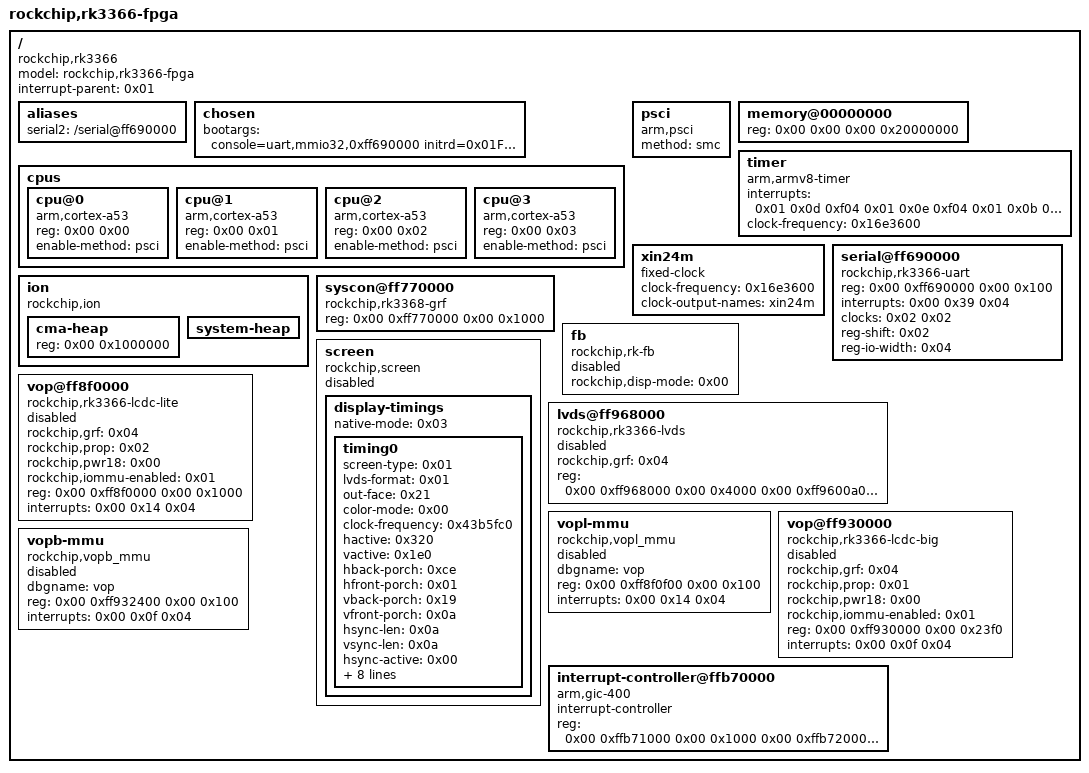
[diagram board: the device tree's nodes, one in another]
/dts-v1/;

/ {
	model = "rockchip,rk3366-fpga";
	compatible = "rockchip,rk3366";
	interrupt-parent = <0x01>;
	#address-cells = <0x02>;
	#size-cells = <0x02>;

	aliases {
		serial2 = "/serial@ff690000";
	};

	chosen {
		bootargs = "console=uart,mmio32,0xff690000 initrd=0x01FFFFF8,0x00800000";
	};

	cpus {
		#address-cells = <0x02>;
		#size-cells = <0x00>;

		cpu@0 {
			device_type = "cpu";
			compatible = "arm,cortex-a53\0arm,armv8";
			reg = <0x00 0x00>;
			enable-method = "psci";
			phandle = <0x05>;
		};

		cpu@1 {
			device_type = "cpu";
			compatible = "arm,cortex-a53\0arm,armv8";
			reg = <0x00 0x01>;
			enable-method = "psci";
			phandle = <0x06>;
		};

		cpu@2 {
			device_type = "cpu";
			compatible = "arm,cortex-a53\0arm,armv8";
			reg = <0x00 0x02>;
			enable-method = "psci";
			phandle = <0x07>;
		};

		cpu@3 {
			device_type = "cpu";
			compatible = "arm,cortex-a53\0arm,armv8";
			reg = <0x00 0x03>;
			enable-method = "psci";
			phandle = <0x08>;
		};
	};

	psci {
		compatible = "arm,psci";
		method = "smc";
	};

	memory@00000000 {
		device_type = "memory";
		reg = <0x00 0x00 0x00 0x20000000>;
	};

	timer {
		compatible = "arm,armv8-timer";
		interrupts = <0x01 0x0d 0xf04 0x01 0x0e 0xf04 0x01 0x0b 0xf04 0x01 0x0a 0xf04>;
		clock-frequency = <0x16e3600>;
	};

	xin24m {
		compatible = "fixed-clock";
		#clock-cells = <0x00>;
		clock-frequency = <0x16e3600>;
		clock-output-names = "xin24m";
		phandle = <0x02>;
	};

	serial@ff690000 {
		compatible = "rockchip,rk3366-uart\0snps,dw-apb-uart";
		reg = <0x00 0xff690000 0x00 0x100>;
		interrupts = <0x00 0x39 0x04>;
		clocks = <0x02 0x02>;
		clock-names = "baudclk\0apb_pclk";
		reg-shift = <0x02>;
		reg-io-width = <0x04>;
		phandle = <0x09>;
	};

	ion {
		compatible = "rockchip,ion";
		#address-cells = <0x01>;
		#size-cells = <0x00>;

		cma-heap {
			reg = <0x00 0x1000000>;
		};

		system-heap {
		};
	};

	syscon@ff770000 {
		compatible = "rockchip,rk3368-grf\0syscon";
		reg = <0x00 0xff770000 0x00 0x1000>;
		phandle = <0x04>;
	};

	fb {
		compatible = "rockchip,rk-fb";
		rockchip,disp-mode = <0x00>;
		status = "disabled";
		phandle = <0x0a>;
	};

	screen {
		compatible = "rockchip,screen";
		status = "disabled";
		phandle = <0x0b>;

		display-timings {
			native-mode = <0x03>;
			phandle = <0x0c>;

			timing0 {
				screen-type = <0x01>;
				lvds-format = <0x01>;
				out-face = <0x21>;
				color-mode = <0x00>;
				clock-frequency = <0x43b5fc0>;
				hactive = <0x320>;
				vactive = <0x1e0>;
				hback-porch = <0xce>;
				hfront-porch = <0x01>;
				vback-porch = <0x19>;
				vfront-porch = <0x0a>;
				hsync-len = <0x0a>;
				vsync-len = <0x0a>;
				hsync-active = <0x00>;
				vsync-active = <0x00>;
				de-active = <0x00>;
				pixelclk-active = <0x00>;
				swap-rb = <0x00>;
				swap-rg = <0x00>;
				swap-gb = <0x00>;
				cabc-lut = <0x00 0x00 0x00 0x00 0x00 0x00 0x00 0x00 0x00 0x00 0x00 0x00 0x00 0x00 0x00 0x00 0x01 0x01 0x01 0x01 0x01 0x01 0x01 0x02 0x02 0x02 0x02 0x02 0x03 0x03 0x03 0x03 0x04 0x04 0x04 0x04 0x05 0x05 0x05 0x05 0x06 0x06 0x06 0x07 0x07 0x07 0x08 0x08 0x09 0x09 0x09 0x0a 0x0a 0x0b 0x0b 0x0b 0x0c 0x0c 0x0d 0x0d 0x0e 0x0e 0x0f 0x0f 0x10 0x10 0x11 0x11 0x12 0x12 0x13 0x13 0x14 0x14 0x15 0x16 0x16 0x17 0x17 0x18 0x19 0x19 0x1a 0x1b 0x1b 0x1c 0x1d 0x1d 0x1e 0x1f 0x1f 0x20 0x21 0x21 0x22 0x23 0x24 0x24 0x25 0x26 0x27 0x28 0x28 0x29 0x2a 0x2b 0x2c 0x2c 0x2d 0x2e 0x2f 0x30 0x31 0x32 0x32 0x33 0x34 0x35 0x36 0x37 0x38 0x39 0x3a 0x3b 0x3c 0x3d 0x3e 0x3f 0x40 0x41 0x42 0x43 0x44 0x45 0x46 0x47 0x48 0x49 0x4a 0x4b 0x4c 0x4d 0x4f 0x50 0x51 0x52 0x53 0x54 0x55 0x57 0x58 0x59 0x5a 0x5b 0x5d 0x5e 0x5f 0x60 0x61 0x63 0x64 0x65 0x66 0x68 0x69 0x6a 0x6c 0x6d 0x6e 0x70 0x71 0x72 0x74 0x75 0x76 0x78 0x79 0x7a 0x7c 0x7d 0x7f 0x80 0x81 0x83 0x84 0x86 0x87 0x89 0x8a 0x8c 0x8d 0x8f 0x90 0x92 0x93 0x95 0x96 0x98 0x99 0x9b 0x9c 0x9e 0xa0 0xa1 0xa3 0xa4 0xa6 0xa8 0xa9 0xab 0xac 0xae 0xb0 0xb1 0xb3 0xb5 0xb6 0xb8 0xba 0xbc 0xbd 0xbf 0xc1 0xc3 0xc4 0xc6 0xc8 0xca 0xcb 0xcd 0xcf 0xd1 0xd3 0xd4 0xd6 0xd8 0xda 0xdc 0xde 0xe0 0xe1 0xe3 0xe5 0xe7 0xe9 0xeb 0xed 0xef 0xf1 0xf3 0xf5 0xf7 0xf9 0xfb 0xfd 0xff>;
				phandle = <0x03>;
			};
		};
	};

	lvds@ff968000 {
		compatible = "rockchip,rk3366-lvds";
		rockchip,grf = <0x04>;
		reg = <0x00 0xff968000 0x00 0x4000 0x00 0xff9600a0 0x00 0x20>;
		reg-names = "mipi_lvds_phy\0mipi_lvds_ctl";
		status = "disabled";
		phandle = <0x0d>;
	};

	vop@ff8f0000 {
		compatible = "rockchip,rk3366-lcdc-lite";
		rockchip,grf = <0x04>;
		rockchip,prop = <0x02>;
		rockchip,pwr18 = <0x00>;
		rockchip,iommu-enabled = <0x01>;
		reg = <0x00 0xff8f0000 0x00 0x1000>;
		interrupts = <0x00 0x14 0x04>;
		status = "disabled";
		phandle = <0x0e>;
	};

	vopl-mmu {
		dbgname = "vop";
		compatible = "rockchip,vopl_mmu";
		reg = <0x00 0xff8f0f00 0x00 0x100>;
		interrupts = <0x00 0x14 0x04>;
		interrupt-names = "vopl_mmu";
		status = "disabled";
		phandle = <0x0f>;
	};

	vop@ff930000 {
		compatible = "rockchip,rk3366-lcdc-big";
		rockchip,grf = <0x04>;
		rockchip,prop = <0x01>;
		rockchip,pwr18 = <0x00>;
		rockchip,iommu-enabled = <0x01>;
		reg = <0x00 0xff930000 0x00 0x23f0>;
		interrupts = <0x00 0x0f 0x04>;
		status = "disabled";
		phandle = <0x10>;
	};

	vopb-mmu {
		dbgname = "vop";
		compatible = "rockchip,vopb_mmu";
		reg = <0x00 0xff932400 0x00 0x100>;
		interrupts = <0x00 0x0f 0x04>;
		interrupt-names = "vop_mmu";
		status = "disabled";
		phandle = <0x11>;
	};

	interrupt-controller@ffb70000 {
		compatible = "arm,gic-400";
		#interrupt-cells = <0x03>;
		#address-cells = <0x00>;
		interrupt-controller;
		reg = <0x00 0xffb71000 0x00 0x1000 0x00 0xffb72000 0x00 0x1000>;
		phandle = <0x01>;
	};

	__symbols__ {
		cpu0 = "/cpus/cpu@0";
		cpu1 = "/cpus/cpu@1";
		cpu2 = "/cpus/cpu@2";
		cpu3 = "/cpus/cpu@3";
		xin24m = "/xin24m";
		uart2 = "/serial@ff690000";
		grf = "/syscon@ff770000";
		fb = "/fb";
		rk_screen = "/screen";
		disp_timings = "/screen/display-timings";
		timing0 = "/screen/display-timings/timing0";
		lvds = "/lvds@ff968000";
		vop_lite = "/vop@ff8f0000";
		vopl_mmu = "/vopl-mmu";
		vop_big = "/vop@ff930000";
		vopb_mmu = "/vopb-mmu";
		gic = "/interrupt-controller@ffb70000";
	};
};
